# ADuCM320i register map
Vendor: Analog Devices Inc.; Series: ARMCM3; File version: 1.0
CPU: CM3 r2p1, little endian, no MPU, no FPU, 3 interrupt priority bits
Registers are 16-bit, read-write, no defined reset value unless marked. A register's access mark holds for its fields unless they carry their own. Offsets are from the block's base; [hi:lo] are bit positions; {n}, {i} and the like mark numbered series.

## LV — Low voltage die ID
Base 0x40082C30
0x00 LVID ro reset 0x71 (reset mask 0x0) — Low voltage die ID
  [15:0] LVID range 0x00000000..0x0000FFFF — LVID comes from hardware coded logic

## LV_RST — Low voltage die reset configuration
Base 0x40082C34
0x00 LVRST — LV die reset configuration
  [0] RETAIN — LV retains status after WDT and software reset
    0=EN (LV die retains status after watchdog or software reset.); 1=DIS (LV die does not retain status after watchdog or software reset.)

## IDAC
Base 0x40086800
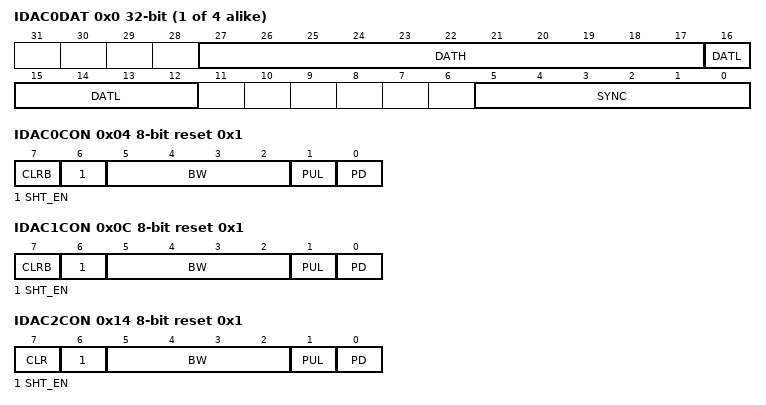
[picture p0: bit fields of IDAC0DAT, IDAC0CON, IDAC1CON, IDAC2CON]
{0x0+8i} IDAC{i}DAT 32-bit (i=0..3) — IDAC{i} data register
  [27:17] DATH range 0x00000000..0x000007FF — IDAC{i} high data
  [16:12] DATL range 0x00000000..0x0000001F — IDAC{i} low data
  [5:0] SYNC range 0x00000000..0x0000003F — IDAC{i} sync bits
0x04 IDAC0CON 8-bit reset 0x1 (reset mask 0x0) — IDAC0 control register
  [7] CLRB range 0x00000000..0x00000001 — IDAC0 Clear bit
  [6] SHT_EN range 0x00000000..0x00000001 — IDAC0 shutdown enable
  [5:2] BW range 0x00000000..0x0000000F — IDAC0 bandwidth
  [1] PUL range 0x00000000..0x00000001 — IDAC0 pull down
  [0] PD — IDAC0 power down
    0=ON (Powers IDAC0 up); 1=OFF (Powers IDAC0 down)
0x0C IDAC1CON 8-bit reset 0x1 (reset mask 0x0) — IDAC1 control register
  [7] CLRB range 0x00000000..0x00000001 — IDAC1 Clear bit
  [6] SHT_EN range 0x00000000..0x00000001 — IDAC1 shutdown enable
  [5:2] BW range 0x00000000..0x0000000F — IDAC1 bandwidth
  [1] PUL range 0x00000000..0x00000001 — IDAC1 pull down
  [0] PD — IDAC1 power down
    0=OFF (Powers IDAC1 up); 1=ON (Powers IDAC1 down)
0x14 IDAC2CON 8-bit reset 0x1 (reset mask 0x0) — IDAC2 control register
  [7] CLR range 0x00000000..0x00000001 — IDAC2 Clear bit
  [6] SHT_EN range 0x00000000..0x00000001 — IDAC2 shutdown enable
  [5:2] BW range 0x00000000..0x0000000F — IDAC2 bandwidth
  [1] PUL range 0x00000000..0x00000001 — IDAC2 pull down
  [0] PD — IDAC2 power down
    0=OFF (Powers IDAC2 up); 1=ON (Powers IDAC2 down)
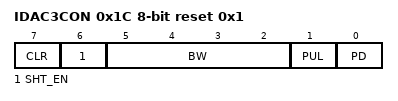
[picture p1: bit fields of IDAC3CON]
0x1C IDAC3CON 8-bit reset 0x1 (reset mask 0x0) — IDAC3 control register
  [7] CLR range 0x00000000..0x00000001 — IDAC3 Clear bit
  [6] SHT_EN range 0x00000000..0x00000001 — IDAC3 shutdown enable
  [5:2] BW range 0x00000000..0x0000000F — IDAC3 bandwidth
  [1] PUL range 0x00000000..0x00000001 — IDAC3 pull down
  [0] PD — IDAC3 power down
    0=OFF (Powers IDAC3 up); 1=ON (Powers IDAC3 down)

## AFE — Analog
Base 0x40087800
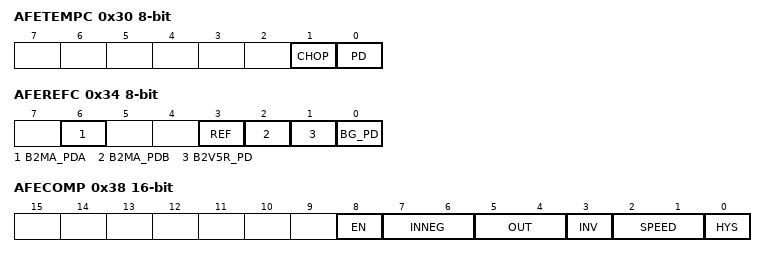
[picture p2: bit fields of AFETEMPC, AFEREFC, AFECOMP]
0x30 AFETEMPC 8-bit — Temp sensor configuration register
  [1] CHOP — Temperature sensor chopping enable.
    0=DIS (Disable chopping mode); 1=EN (Enable chopping mode)
  [0] PD — Temperature sensor power down.
    0=DIS (Power up temp sensor); 1=EN (Power down temp sensor)
0x34 AFEREFC 8-bit — Reference configuration register
  [6] B2MA_PDA — Power down the reference 2mA output driving buffer A.
    0=DIS (Power up 2.5 V reference output driving buffer A); 1=EN (Power down 2.5 V reference output driving buffer A)
  [3] REF — bypass the internal reference, and select the external reference.
    0=INT (Select internal 2.5v reference); 1=EXT (Select external 2.5v reference)
  [2] B2MA_PDB — Power down the reference 2mA output driving buffer B.
    0=DIS (Power up 2.5 V reference output driving buffer B); 1=EN (Power down 2.5 V reference output driving buffer B)
  [1] B2V5R_PD — 2.5v reference buffer power down
    0=DIS (Power up 2.5 V reference buffer); 1=EN (Power down 2.5 V reference buffer)
  [0] BG_PD — Bandgap power down
    0=DIS (Power up 1.2 V bandgap); 1=EN (Power down 1.2 V bandgap)
0x38 AFECOMP — Analog comparator configuration register
  [8] EN — Powers up and enables comparator
    0=DIS (Power down and disable comparator); 1=EN (Power up and enable comparator)
  [7:6] INNEG — Selects comparator negative input signal.
    0=AVDD2; 1=AIN5; 2=DAC7
  [5:4] OUT — Connects comparator output to interrupt logic.
    0=DIS (Do not connect output); 1=EN (Connect output to interrupt logic)
  [3] INV — Selects output logic state.
    0=NO (Output will be high if +ve input is above -ve input.); 1=YES (Output will be high if +ve input is below -ve input.)
  [2:1] SPEED — Selects comparator speed.
    0=6.00us; 1=3.25us; 2=1.75us; 3=1.00us
  [0] HYS — Enables comparator hysteresis
    0=DIS (Disable hysteresis); 1=EN (Enable hysteresis)

## NVIC — Nested Vectored Interrupt Controller
Base 0xE000E000
0x04 ICTR 32-bit ro — Interrupt Controller Type Register
  [3:0] INTLINESNUM — Total number of interrupt lines in groups
0x100 ISER0 32-bit — Interrupt Set-Enable Register
  [31:0] SETENA
0x104 ISER1 32-bit — Interrupt Set-Enable Register
  [31:0] SETENA
0x180 ICER0 32-bit — Interrupt Clear-Enable Register
  [31:0] CLRENA
0x184 ICER1 32-bit — Interrupt Clear-Enable Register
  [31:0] CLRENA
0x200 ISPR0 32-bit — Interrupt Set-Pending Register
  [31:0] SETPEND
0x204 ISPR1 32-bit — Interrupt Set-Pending Register
  [31:0] SETPEND
0x280 ICPR0 32-bit — Interrupt Clear-Pending Register
  [31:0] CLRPEND
0x284 ICPR1 32-bit — Interrupt Clear-Pending Register
  [31:0] CLRPEND
0x300 IABR0 32-bit ro — Interrupt Active Bit Register
  [31:0] ACTIVE
0x304 IABR1 32-bit ro — Interrupt Active Bit Register
  [31:0] ACTIVE
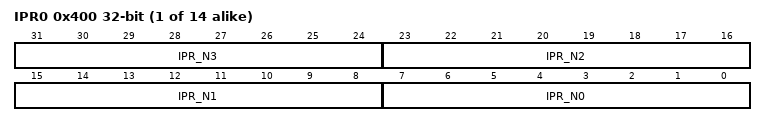
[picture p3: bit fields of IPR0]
{0x400+4i} IPR{i} 32-bit (i=0..13) — Interrupt Priority Register
  [8n+7:8n] IPR_N{n} (n=0..3)
0xF00 STIR 32-bit wo — Software Triggered Interrupt Register
  [8:0] INTID — interrupt to be triggered
